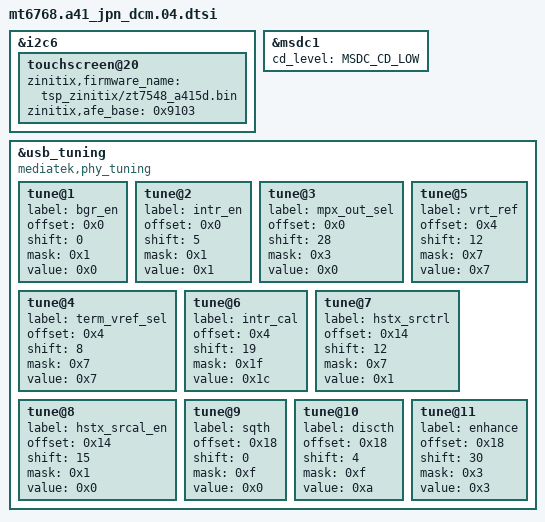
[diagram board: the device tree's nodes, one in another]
/*
 * Generated by Samsung
 * If these files should be changed, then please make a sync with MTK
*/

#include "../../mediatek/k68v1_64_titan/gpio00_a41_jpn.dtsi"
#include "mt6768-a41_common.dtsi"
#include "mt6768-a41_camera_02.dtsi"
#include "s2mu106_motor.dtsi"
#include "mt6768-a41_input_common.dtsi"
#include "mt6768-a41_pm_common.dtsi"
#include "mt6768-a41_audio_common.dtsi"

/* Add Samsung configuration over here */

&i2c6 {
	touchscreen@20 {
		zinitix,firmware_name = "tsp_zinitix/zt7548_a415d.bin";
		zinitix,afe_base = <0x9103>;
	};
};

&msdc1 {
	cd_level = /bits/ 8 <MSDC_CD_LOW>;
};

&usb_tuning {
	compatible = "mediatek,phy_tuning";
	tune@1 {
		label = "bgr_en";
		offset = <0x0>;
		shift = <0>;
		mask = <0x1>;
		value = <0x0>;
	};
	tune@2 {
		label = "intr_en";
		offset = <0x0>;
		shift = <5>;
		mask = <0x1>;
		value = <0x1>;
	};
	tune@3 {
		label = "mpx_out_sel";
		offset = <0x0>;
		shift = <28>;
		mask = <0x3>;
		value = <0x0>;
	};
	tune@4 {
		label = "term_vref_sel";
		offset = <0x4>;
		shift = <8>;
		mask = <0x7>;
		value = <0x7>;
	};
	tune@5 {
		label = "vrt_ref";
		offset = <0x4>;
		shift = <12>;
		mask = <0x7>;
		value = <0x7>;
	};
	tune@6 {
		label = "intr_cal";
		offset = <0x4>;
		shift = <19>;
		mask = <0x1f>;
		value = <0x1c>;
	};
	tune@7 {
		label = "hstx_srctrl";
		offset = <0x14>;
		shift = <12>;
		mask = <0x7>;
		value = <0x1>;
	};
	tune@8 {
		label = "hstx_srcal_en";
		offset = <0x14>;
		shift = <15>;
		mask = <0x1>;
		value = <0x0>;
	};
	tune@9 {
		label = "sqth";
		offset = <0x18>;
		shift = <0>;
		mask = <0xf>;
		value = <0x0>;
	};
	tune@10 {
		label = "discth";
		offset = <0x18>;
		shift = <4>;
		mask = <0xf>;
		value = <0xa>;
	};
	tune@11 {
		label = "enhance";
		offset = <0x18>;
		shift = <30>;
		mask = <0x3>;
		value = <0x3>;
	};
};

/*End of this file, DO NOT ADD ANYTHING HERE*/
